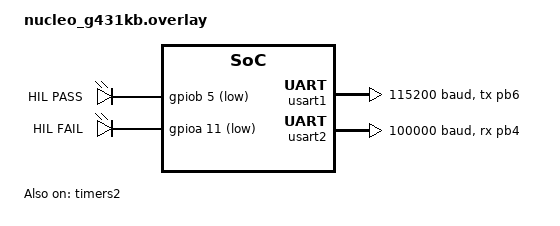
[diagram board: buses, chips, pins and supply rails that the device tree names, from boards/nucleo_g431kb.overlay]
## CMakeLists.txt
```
# SPDX-License-Identifier: Apache-2.0

cmake_minimum_required(VERSION 3.28.0)
find_package(Zephyr REQUIRED HINTS $ENV{ZEPHYR_BASE})
project(sbus_bridge_hil)

target_sources(app PRIVATE
  src/main.c
  src/frame.c
)
```

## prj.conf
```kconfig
# SPDX-License-Identifier: Apache-2.0

CONFIG_ZTEST=y
CONFIG_ZTEST_FAIL_FAST=y
CONFIG_SHELL=y
CONFIG_REBOOT=y
CONFIG_SERIAL=y
CONFIG_UART_INTERRUPT_DRIVEN=y
CONFIG_CRC=y
CONFIG_GPIO=y
CONFIG_COUNTER=y
CONFIG_COUNTER_CAPTURE=y
```

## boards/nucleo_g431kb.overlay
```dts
/*
 * SPDX-License-Identifier: Apache-2.0
 *
 * Wiring (with DUT sbus_bridge):
 *   PB6 (D6)   USART1 TX 115200 8N1         -> DUT UART in
 *   PB4 (D12)  USART2 RX 100k 8E2 rx-invert <- DUT S.BUS out
 *   PA0 (A0)   TIM2_CH1 jumpered to PB6 (UART start, falling)
 *   PA1 (A1)   TIM2_CH2 jumpered to PB4 (S.BUS start, rising)
 *   PB5 (D11)  green status LED, OD active-low to +5 V
 *   PA11 (D10) red status LED, OD active-low to +5 V
 * Console LPUART1 PA2/PA3 untouched.
 */

#include <zephyr/dt-bindings/gpio/gpio.h>

/ {
	aliases {
		uart-out = &usart1;
		sbus-in = &usart2;
		led-green = &hil_led_green;
		led-red = &hil_led_red;
	};
};

&leds {
	hil_led_green: led_green {
		gpios = <&gpiob 5 (GPIO_OPEN_DRAIN | GPIO_ACTIVE_LOW)>;
		label = "HIL PASS";
	};

	hil_led_red: led_red {
		gpios = <&gpioa 11 (GPIO_OPEN_DRAIN | GPIO_ACTIVE_LOW)>;
		label = "HIL FAIL";
	};
};

&usart1 {
	pinctrl-0 = <&usart1_tx_pb6>;
	pinctrl-names = "default";
	current-speed = <115200>;
	fifo-enable;
	interrupts = <37 1>;
	status = "okay";
};

&usart2 {
	pinctrl-0 = <&usart2_rx_pb4>;
	pinctrl-names = "default";
	current-speed = <100000>;
	parity = "even";
	stop-bits = "2";
	rx-invert;
	fifo-enable;
	interrupts = <38 1>;
	status = "okay";
};

&timers2 {
	st,prescaler = <16>;
	status = "okay";

	counter2: counter {
		status = "okay";
		pinctrl-0 = <&tim2_ch1_pa0 &tim2_ch2_pa1>;
		pinctrl-names = "default";
	};
};
```

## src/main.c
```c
/*
 * SPDX-License-Identifier: Apache-2.0
 */

#include <stdbool.h>
#include <stddef.h>
#include <stdint.h>

#include <zephyr/kernel.h>
#include <zephyr/sys/util.h>
#include <zephyr/ztest.h>

#include "capture.h"
#include "frame.h"
#include "status_led.h"
#include "wire.h"

#define HIL_STREAM_N               100
#define HIL_PACED_PERIOD_MS        5 /* 200 Hz */
#define HIL_PACED_SEND_GAP_MIN_US  3000
#define HIL_PACED_SEND_GAP_MAX_US  7000
#define HIL_RTT_MIN_US             50
#define HIL_RTT_MAX_US             200
#define HIL_GAPLESS_RX_MIN         70
#define HIL_GAPLESS_RX_MAX         80
#define HIL_GAPLESS_SEND_GAP_MIN_US 1000
#define HIL_GAPLESS_SEND_GAP_MAX_US 6000
#define HIL_UART_BYTE_US           87 /* 10/115200 ~= 86.8 */
#define HIL_FRAME_UART_US          (HIL_FRAME_LEN * HIL_UART_BYTE_US)
#define HIL_IDLE_MS                20
#define HIL_SETTLE_MS              5
#define HIL_FIRST_FRAME_TO_MS      50
#define HIL_SETTLE_TIMEOUT_MS      2000
#define HIL_CAPTURE_TIMEOUT_MS     20
#define HIL_NOISE_N                512
#define HIL_NOISE_SEED             0xC0FFEEu
#define HIL_NOISE_SEQ              0x4E01u

static bool eol_any_failed(void)
{
	struct ztest_unit_test *test = NULL;

	while ((test = z_ztest_get_next_test("eol", test)) != NULL) {
		if (test->stats->fail_count > 0U) {
			return true;
		}
	}

	return false;
}

static uint32_t now_us(void)
{
	/* 32-bit cycle-to-us wraps in ~25 s; short-stream diffs are modular. */
	return k_cyc_to_us_near32(k_cycle_get_32());
}

/* Wait until no RX byte has been seen for HIL_SETTLE_MS. */
static void settle(void)
{
	int64_t deadline = k_uptime_get() + HIL_SETTLE_TIMEOUT_MS;

	while (k_uptime_get() < deadline) {
		int64_t last = hil_wire_last_rx_ms();

		if (last < 0 || (k_uptime_get() - last) >= HIL_SETTLE_MS) {
			return;
		}
		k_msleep(1);
	}

	zassert_unreachable("DUT output did not settle within %d ms", HIL_SETTLE_TIMEOUT_MS);
}

static void *eol_setup(void)
{
	zassert_ok(hil_status_leds_init());
	hil_status_leds_off();

	zassert_ok(hil_wire_init());
	/* Close any stuck DUT COLLECT window left by a prior failed run. */
	zassert_ok(hil_wire_drain());
	/* Drain may start a junk S.BUS frame after our TX completes. */
	k_msleep(HIL_SETTLE_MS);
	settle();
	hil_wire_reset();
	zassert_ok(hil_capture_init());
	return NULL;
}

static void eol_teardown(void *data)
{
	ARG_UNUSED(data);

	if (eol_any_failed()) {
		hil_status_leds_fail();
	} else {
		hil_status_leds_pass();
	}
}

static void assert_stream(const char *name, uint32_t sent_last, size_t rx_min, size_t rx_max,
			  uint32_t seq_gap_max, uint32_t send_gap_min_us, uint32_t send_gap_max_us,
			  bool check_idle)
{
	uint32_t seq_gap_lo = UINT32_MAX;
	uint32_t seq_gap_hi = 0U;
	uint32_t send_gap_lo = UINT32_MAX;
	uint32_t send_gap_hi = 0U;
	uint32_t prev_seq = 0U;
	uint32_t prev_t_us = 0U;
	uint32_t seq = 0U;
	uint32_t t_us = 0U;
	size_t count;

	/* Let the tail of the DUT output arrive before judging the stream. */
	settle();

	int64_t idle_since = hil_wire_last_rx_ms() + 1;
	size_t rx_at_settle = hil_wire_rx_count();
	uint32_t corrupt_at_settle = hil_wire_corrupt_count();

	zassert_equal(corrupt_at_settle, 0, "%s: corrupt frames/bytes seen", name);

	count = hil_wire_rx_count();
	zassert_true(count >= rx_min && count <= rx_max, "%s: rx_count %zu outside [%zu, %zu]",
		     name, count, rx_min, rx_max);

	for (size_t i = 0; i < count; i++) {
		zassert_true(hil_wire_rx_get(i, &seq, &t_us), "%s: rx_get(%zu) failed", name, i);

		if (i > 0) {
			uint32_t seq_gap = seq - prev_seq;
			uint32_t send_gap = t_us - prev_t_us; /* modular */

			zassert_true(seq > prev_seq && seq_gap >= 1U && seq_gap <= seq_gap_max,
				     "%s: seq gap %u at rx %zu (seq %u -> %u), max %u", name,
				     seq_gap, i, prev_seq, seq, seq_gap_max);
			zassert_true(send_gap >= send_gap_min_us && send_gap <= send_gap_max_us,
				     "%s: send gap %u us at rx %zu (seq %u -> %u), want [%u, %u]",
				     name, send_gap, i, prev_seq, seq, send_gap_min_us,
				     send_gap_max_us);

			seq_gap_lo = MIN(seq_gap_lo, seq_gap);
			seq_gap_hi = MAX(seq_gap_hi, seq_gap);
			send_gap_lo = MIN(send_gap_lo, send_gap);
			send_gap_hi = MAX(send_gap_hi, send_gap);
		}

		prev_seq = seq;
		prev_t_us = t_us;
	}

	zassert_equal(seq, sent_last, "%s: last seq %u != sent %u", name, seq, sent_last);

	TC_PRINT("%s: rx=%zu seq_gap[min=%u max=%u] send_gap_us[min=%u max=%u]\n", name, count,
		 seq_gap_lo, seq_gap_hi, send_gap_lo, send_gap_hi);

	if (check_idle) {
		k_msleep(HIL_IDLE_MS);
		zassert_true(hil_wire_idle_since(idle_since, HIL_IDLE_MS),
			     "%s: unexpected RX after final frame", name);
		zassert_equal(hil_wire_rx_count(), rx_at_settle, "%s: rx_count changed during idle",
			      name);
		zassert_equal(hil_wire_corrupt_count(), corrupt_at_settle,
			      "%s: corrupt count changed during idle", name);
	}
}

ZTEST(eol, test_frame_crc_vector)
{
	uint8_t frame[HIL_FRAME_LEN];
	uint32_t seq;
	uint32_t t_us;
	static const uint8_t expect[HIL_FRAME_LEN] = {
		0x0f, 0x00, 0x00, 0x00, 0x00, 0x04, 0x03, 0x02, 0x01,
		0x5a, 0x5a, 0x5a, 0x5a, 0x5a, 0x5a, 0x5a, 0x5a, 0x5a,
		0x5a, 0x5a, 0x5a, 0x04, 0x2b, 0x00, 0x00,
	};

	hil_frame_encode(frame, 0, 0x01020304);
	zassert_mem_equal(frame, expect, HIL_FRAME_LEN);
	zassert_true(hil_frame_check(frame, &seq, &t_us));
	zassert_equal(seq, 0);
	zassert_equal(t_us, 0x01020304);
	frame[21] ^= 0x01;
	zassert_false(hil_frame_check(frame, &seq, &t_us));
}

ZTEST(eol, test_cut_through)
{
	uint8_t frame[HIL_FRAME_LEN];
	uint32_t t_uart;
	uint32_t t_sbus;
	uint32_t seq;
	uint32_t t_us;
	uint32_t rtt_us;

	settle();
	hil_wire_reset();
	zassert_ok(hil_capture_arm());

	hil_frame_encode(frame, 0, now_us());
	/* Armed before send so the UART falling edge is not missed. */
	zassert_ok(hil_wire_send_frame(frame));

	zassert_ok(hil_capture_wait(&t_uart, &t_sbus, K_MSEC(HIL_CAPTURE_TIMEOUT_MS)));
	hil_capture_disarm();

	/* Cut-through: S.BUS start appears before the input frame would have finished. */
	rtt_us = hil_capture_ticks_to_us(t_sbus - t_uart); /* modular 32-bit subtract */
	zassert_true(rtt_us < HIL_FRAME_UART_US, "rtt %u us is not < frame time %u us", rtt_us,
		     HIL_FRAME_UART_US);

	/* The whole valid frame must follow. */
	zassert_true(WAIT_FOR(hil_wire_rx_count() >= 1, 50000, k_msleep(1)),
		     "no complete frame on S.BUS");
	settle();
	zassert_equal(hil_wire_rx_count(), 1);
	zassert_equal(hil_wire_corrupt_count(), 0);
	zassert_true(hil_wire_rx_get(0, &seq, &t_us));
	zassert_equal(seq, 0);

	TC_PRINT("cut-through rtt=%u us\n", rtt_us);
}

ZTEST(eol, test_paced)
{
	uint8_t frame[HIL_FRAME_LEN];
	uint32_t rtt_min_us = UINT32_MAX;
	uint32_t rtt_max_us = 0U;
	int64_t start_ms;

	settle();
	hil_wire_reset();

	start_ms = k_uptime_get();
	for (uint32_t i = 0; i < HIL_STREAM_N; i++) {
		uint32_t t_uart;
		uint32_t t_sbus;
		uint32_t rtt_us;

		zassert_ok(hil_capture_arm());
		hil_frame_encode(frame, i, now_us());
		zassert_ok(hil_wire_send_frame(frame));
		zassert_ok(hil_capture_wait(&t_uart, &t_sbus, K_MSEC(HIL_CAPTURE_TIMEOUT_MS)),
			   "frame %u: no capture", i);
		hil_capture_disarm();

		rtt_us = hil_capture_ticks_to_us(t_sbus - t_uart);
		zassert_true(rtt_us >= HIL_RTT_MIN_US && rtt_us <= HIL_RTT_MAX_US,
			     "frame %u: rtt %u us outside [%u, %u]", i, rtt_us, HIL_RTT_MIN_US,
			     HIL_RTT_MAX_US);
		rtt_min_us = MIN(rtt_min_us, rtt_us);
		rtt_max_us = MAX(rtt_max_us, rtt_us);

		if (i == 0U) {
			/* First valid frame must be out within HIL_FIRST_FRAME_TO_MS of send. */
			zassert_true(WAIT_FOR(hil_wire_rx_count() >= 1,
					      (HIL_FIRST_FRAME_TO_MS -
					       (k_uptime_get() - start_ms)) * USEC_PER_MSEC,
					      k_msleep(1)),
				     "no valid frame within %d ms of first send",
				     HIL_FIRST_FRAME_TO_MS);
		}

		k_sleep(K_TIMEOUT_ABS_MS(start_ms + (int64_t)(i + 1U) * HIL_PACED_PERIOD_MS));
	}

	TC_PRINT("paced: rtt_us[min=%u max=%u]\n", rtt_min_us, rtt_max_us);

	assert_stream("paced", HIL_STREAM_N - 1, HIL_STREAM_N, HIL_STREAM_N, 1,
		      HIL_PACED_SEND_GAP_MIN_US, HIL_PACED_SEND_GAP_MAX_US, true);
}

ZTEST(eol, test_gapless)
{
	uint8_t frame[HIL_FRAME_LEN];

	settle();
	hil_wire_reset();
	hil_capture_disarm();

	for (uint32_t i = 0; i < HIL_STREAM_N; i++) {
		hil_frame_encode(frame, i, now_us());
		zassert_ok(hil_wire_send_frame(frame), "frame %u: send failed", i);
	}

	assert_stream("gapless", HIL_STREAM_N - 1, HIL_GAPLESS_RX_MIN, HIL_GAPLESS_RX_MAX, 2,
		      HIL_GAPLESS_SEND_GAP_MIN_US, HIL_GAPLESS_SEND_GAP_MAX_US, true);
}

/* xorshift32; not crypto — reproducible flood for HIL. */
static uint32_t xorshift32(uint32_t *state)
{
	uint32_t x = *state;

	x ^= x << 13;
	x ^= x >> 17;
	x ^= x << 5;
	*state = x;
	return x;
}

static void flood_noise(bool allow_header)
{
	uint8_t chunk[HIL_FRAME_LEN];
	uint32_t rng = HIL_NOISE_SEED;
	size_t left = HIL_NOISE_N;

	while (left > 0U) {
		size_t n = MIN(left, sizeof(chunk));

		for (size_t i = 0; i < n; i++) {
			uint8_t b = (uint8_t)xorshift32(&rng);

			if (!allow_header && b == HIL_HDR) {
				b ^= 0x01U;
			}
			chunk[i] = b;
		}
		zassert_ok(hil_wire_send_bytes(chunk, n), "noise send failed (%zu left)", left);
		left -= n;
	}
}

static void assert_recovery_frame(const char *name)
{
	uint8_t frame[HIL_FRAME_LEN];
	uint32_t seq;
	uint32_t t_us;

	hil_frame_encode(frame, HIL_NOISE_SEQ, now_us());
	zassert_ok(hil_wire_send_frame(frame));

	zassert_true(WAIT_FOR(hil_wire_rx_count() >= 1, 50000, k_msleep(1)),
		     "%s: no complete frame on S.BUS after recovery send", name);
	settle();
	zassert_equal(hil_wire_rx_count(), 1, "%s: expected exactly one logged frame", name);
	zassert_equal(hil_wire_corrupt_count(), 0, "%s: corrupt after recovery", name);
	zassert_true(hil_wire_rx_get(0, &seq, &t_us), "%s: rx_get failed", name);
	zassert_equal(seq, HIL_NOISE_SEQ, "%s: seq %u != %u", name, seq, HIL_NOISE_SEQ);

	TC_PRINT("%s: recovered seq=%u\n", name, seq);
}

ZTEST(eol, test_noise_no_header)
{
	/* Case C: noise without 0x0F keeps DUT in HUNT; one valid frame must pass. */
	settle();
	hil_wire_reset();
	hil_capture_disarm();

	flood_noise(false);
	settle();
	hil_wire_reset();

	assert_recovery_frame("noise_no_header");
}

ZTEST(eol, test_noise_resync)
{
	/* Case A: unrestricted noise may mid-COLLECT; drain then one valid frame. */
	settle();
	hil_wire_reset();
	hil_capture_disarm();

	flood_noise(true);
	zassert_ok(hil_wire_drain());
	k_msleep(HIL_SETTLE_MS);
	settle();
	hil_wire_reset();

	assert_recovery_frame("noise_resync");
}

ZTEST_SUITE(eol, NULL, eol_setup, NULL, NULL, eol_teardown);
```

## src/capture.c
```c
/*
 * SPDX-License-Identifier: Apache-2.0
 */

#include "capture.h"

#include <zephyr/device.h>
#include <zephyr/drivers/counter.h>
#include <zephyr/sys/atomic.h>
#include <zephyr/sys/util.h>

#define UART_CAPTURE_CHANNEL  0U
#define SBUS_CAPTURE_CHANNEL  1U
#define CAPTURE_COMPLETE_MASK (BIT(UART_CAPTURE_CHANNEL) | BIT(SBUS_CAPTURE_CHANNEL))

static const struct device *const capture_dev = DEVICE_DT_GET(DT_NODELABEL(counter2));
static uint32_t uart_ticks;
static uint32_t sbus_ticks;
static atomic_t capture_mask;
K_SEM_DEFINE(capture_done, 0, 1);

/*
 * The STM32 Zephyr counter driver does not expose CCxOF here, so overcapture
 * cannot fail a case; a missed edge still times out from hil_capture_wait()
 * with -EAGAIN.
 */
static void capture_cb(const struct device *dev, uint8_t channel,
		       counter_capture_flags_t flags, uint32_t ticks, void *user_data)
{
	atomic_val_t previous;

	ARG_UNUSED(dev);
	ARG_UNUSED(flags);
	ARG_UNUSED(user_data);

	if (channel != UART_CAPTURE_CHANNEL && channel != SBUS_CAPTURE_CHANNEL) {
		return;
	}

	if (channel == UART_CAPTURE_CHANNEL) {
		uart_ticks = ticks;
	} else {
		sbus_ticks = ticks;
	}

	previous = atomic_or(&capture_mask, BIT(channel));
	if ((previous | BIT(channel)) == CAPTURE_COMPLETE_MASK) {
		k_sem_give(&capture_done);
	}
}

static int capture_configure(void)
{
	int ret;

	ret = counter_capture_configure(capture_dev, UART_CAPTURE_CHANNEL,
					COUNTER_CAPTURE_FALLING_EDGE | COUNTER_CAPTURE_SINGLE_SHOT,
					capture_cb, NULL);
	if (ret != 0) {
		return ret;
	}

	ret = counter_capture_configure(capture_dev, SBUS_CAPTURE_CHANNEL,
					COUNTER_CAPTURE_RISING_EDGE | COUNTER_CAPTURE_SINGLE_SHOT,
					capture_cb, NULL);
	if (ret != 0) {
		(void)counter_disable_capture(capture_dev, UART_CAPTURE_CHANNEL);
	}

	return ret;
}

int hil_capture_init(void)
{
	int ret;

	if (!device_is_ready(capture_dev)) {
		return -ENODEV;
	}

	ret = capture_configure();
	if (ret != 0) {
		return ret;
	}

	ret = counter_start(capture_dev);
	if (ret != 0) {
		hil_capture_disarm();
	}

	return ret;
}

int hil_capture_arm(void)
{
	int ret;

	hil_capture_disarm();

	ret = capture_configure();
	if (ret != 0) {
		return ret;
	}

	k_sem_reset(&capture_done);
	atomic_clear(&capture_mask);
	uart_ticks = 0U;
	sbus_ticks = 0U;

	ret = counter_enable_capture(capture_dev, UART_CAPTURE_CHANNEL);
	if (ret != 0) {
		hil_capture_disarm();
		return ret;
	}

	ret = counter_enable_capture(capture_dev, SBUS_CAPTURE_CHANNEL);
	if (ret != 0) {
		hil_capture_disarm();
	}

	return ret;
}

int hil_capture_wait(uint32_t *t_uart, uint32_t *t_sbus, k_timeout_t timeout)
{
	int ret;

	if (t_uart == NULL || t_sbus == NULL) {
		return -EINVAL;
	}

	ret = k_sem_take(&capture_done, timeout);
	if (ret != 0) {
		return -EAGAIN;
	}

	if (atomic_get(&capture_mask) != CAPTURE_COMPLETE_MASK) {
		return -EIO;
	}

	*t_uart = uart_ticks;
	*t_sbus = sbus_ticks;
	return 0;
}

uint32_t hil_capture_ticks_to_us(uint32_t ticks)
{
	return (uint32_t)counter_ticks_to_us(capture_dev, ticks);
}

void hil_capture_disarm(void)
{
	(void)counter_disable_capture(capture_dev, UART_CAPTURE_CHANNEL);
	(void)counter_disable_capture(capture_dev, SBUS_CAPTURE_CHANNEL);
}
```

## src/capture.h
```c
/*
 * SPDX-License-Identifier: Apache-2.0
 */

#ifndef SBUS_BRIDGE_HIL_CAPTURE_H_
#define SBUS_BRIDGE_HIL_CAPTURE_H_

#include <stdint.h>

#include <zephyr/kernel.h>

int hil_capture_init(void);
int hil_capture_arm(void);
int hil_capture_wait(uint32_t *t_uart, uint32_t *t_sbus, k_timeout_t timeout);
uint32_t hil_capture_ticks_to_us(uint32_t ticks);
void hil_capture_disarm(void);

#endif
```

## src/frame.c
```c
/*
 * SPDX-License-Identifier: Apache-2.0
 */

#include "frame.h"

#include <string.h>

#include <zephyr/sys/byteorder.h>
#include <zephyr/sys/crc.h>

void hil_frame_encode(uint8_t out[HIL_FRAME_LEN], uint32_t seq, uint32_t t_us)
{
	uint16_t crc;

	out[0] = HIL_HDR;
	sys_put_le32(seq, &out[1]);
	sys_put_le32(t_us, &out[5]);
	memset(&out[9], HIL_FILL, 12);
	crc = crc16_itu_t(0xFFFF, &out[1], 20);
	sys_put_le16(crc, &out[21]);
	out[23] = 0x00;
	out[24] = HIL_FTR;
}

bool hil_frame_check(const uint8_t in[HIL_FRAME_LEN], uint32_t *seq, uint32_t *t_us)
{
	uint16_t expect;

	if (in[0] != HIL_HDR || in[23] != 0x00 || in[24] != HIL_FTR) {
		return false;
	}
	expect = crc16_itu_t(0xFFFF, &in[1], 20);
	if (sys_get_le16(&in[21]) != expect) {
		return false;
	}
	*seq = sys_get_le32(&in[1]);
	*t_us = sys_get_le32(&in[5]);
	return true;
}
```

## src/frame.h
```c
/*
 * SPDX-License-Identifier: Apache-2.0
 */

#ifndef SBUS_BRIDGE_HIL_FRAME_H_
#define SBUS_BRIDGE_HIL_FRAME_H_

#include <stdbool.h>
#include <stdint.h>

#define HIL_FRAME_LEN 25
#define HIL_HDR       0x0F
#define HIL_FTR       0x00
#define HIL_FILL      0x5A

void hil_frame_encode(uint8_t out[HIL_FRAME_LEN], uint32_t seq, uint32_t t_us);
bool hil_frame_check(const uint8_t in[HIL_FRAME_LEN], uint32_t *seq, uint32_t *t_us);

#endif
```

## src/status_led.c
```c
/*
 * SPDX-License-Identifier: Apache-2.0
 */

#include "status_led.h"

#include <zephyr/device.h>
#include <zephyr/drivers/gpio.h>

#define LED_GREEN_NODE DT_ALIAS(led_green)
#define LED_RED_NODE   DT_ALIAS(led_red)

BUILD_ASSERT(DT_NODE_EXISTS(LED_GREEN_NODE), "alias led-green missing");
BUILD_ASSERT(DT_NODE_EXISTS(LED_RED_NODE), "alias led-red missing");

static const struct gpio_dt_spec led_green = GPIO_DT_SPEC_GET(LED_GREEN_NODE, gpios);
static const struct gpio_dt_spec led_red = GPIO_DT_SPEC_GET(LED_RED_NODE, gpios);

int hil_status_leds_init(void)
{
	if (!gpio_is_ready_dt(&led_green) || !gpio_is_ready_dt(&led_red)) {
		return -ENODEV;
	}

	if (gpio_pin_configure_dt(&led_green, GPIO_OUTPUT_INACTIVE) < 0 ||
	    gpio_pin_configure_dt(&led_red, GPIO_OUTPUT_INACTIVE) < 0) {
		return -EIO;
	}

	return 0;
}

void hil_status_leds_off(void)
{
	(void)gpio_pin_set_dt(&led_green, 0);
	(void)gpio_pin_set_dt(&led_red, 0);
}

void hil_status_leds_pass(void)
{
	(void)gpio_pin_set_dt(&led_red, 0);
	(void)gpio_pin_set_dt(&led_green, 1);
}

void hil_status_leds_fail(void)
{
	(void)gpio_pin_set_dt(&led_green, 0);
	(void)gpio_pin_set_dt(&led_red, 1);
}
```

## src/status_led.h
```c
/*
 * SPDX-License-Identifier: Apache-2.0
 */

#ifndef SBUS_BRIDGE_HIL_STATUS_LED_H_
#define SBUS_BRIDGE_HIL_STATUS_LED_H_

int hil_status_leds_init(void);
void hil_status_leds_off(void);
void hil_status_leds_pass(void);
void hil_status_leds_fail(void);

#endif
```

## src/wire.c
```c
/*
 * SPDX-License-Identifier: Apache-2.0
 */

#include "wire.h"

#include <errno.h>
#include <string.h>

#include <zephyr/device.h>
#include <zephyr/drivers/uart.h>
#include <zephyr/kernel.h>
#include <zephyr/sys/atomic.h>
#include <zephyr/sys/util.h>

#define UART_OUT_NODE  DT_ALIAS(uart_out)
#define SBUS_IN_NODE   DT_ALIAS(sbus_in)
#define HIL_RX_LOG_MAX 128

BUILD_ASSERT(DT_NODE_EXISTS(UART_OUT_NODE), "alias uart-out missing");
BUILD_ASSERT(DT_NODE_EXISTS(SBUS_IN_NODE), "alias sbus-in missing");
BUILD_ASSERT(DT_IRQ(UART_OUT_NODE, priority) == 1, "uart-out IRQ priority must be 1");
BUILD_ASSERT(DT_IRQ(SBUS_IN_NODE, priority) == 1, "sbus-in IRQ priority must be 1");

struct hil_rx_entry {
	uint32_t seq;
	uint32_t t_us;
};

static const struct device *const uart_out = DEVICE_DT_GET(UART_OUT_NODE);
static const struct device *const sbus_in = DEVICE_DT_GET(SBUS_IN_NODE);
static struct hil_rx_entry rx_log[HIL_RX_LOG_MAX];
static atomic_t rx_count;
static atomic_t corrupt_count;
static uint8_t rx_frame[HIL_FRAME_LEN];
static size_t rx_pos;
static int64_t last_rx_ms = -1;
static uint8_t tx_buf[HIL_FRAME_LEN];
static size_t tx_len;
static size_t tx_pos;
K_SEM_DEFINE(tx_done, 0, 1);
K_MUTEX_DEFINE(tx_lock);

static void uart_out_cb(const struct device *dev, void *user_data)
{
	int sent;

	ARG_UNUSED(user_data);

	uart_irq_update(dev);
	while (tx_pos < tx_len && uart_irq_tx_ready(dev) > 0) {
		sent = uart_fifo_fill(dev, &tx_buf[tx_pos], tx_len - tx_pos);
		if (sent <= 0) {
			break;
		}
		tx_pos += (size_t)sent;
	}

	if (tx_pos == tx_len) {
		uart_irq_tx_disable(dev);
		k_sem_give(&tx_done);
	}
}

static int hil_wire_send(const uint8_t *data, size_t len)
{
	int ret;

	if (data == NULL || len == 0U || len > sizeof(tx_buf)) {
		return -EINVAL;
	}

	k_mutex_lock(&tx_lock, K_FOREVER);
	k_sem_reset(&tx_done);
	memcpy(tx_buf, data, len);
	tx_len = len;
	tx_pos = 0U;
	uart_irq_tx_enable(uart_out);
	ret = k_sem_take(&tx_done, K_MSEC(50));
	if (ret != 0) {
		uart_irq_tx_disable(uart_out);
	}
	k_mutex_unlock(&tx_lock);

	return ret;
}

static void rx_byte(uint8_t byte)
{
	uint32_t seq;
	uint32_t t_us;
	atomic_val_t count;

	last_rx_ms = k_uptime_get();

	if (rx_pos == 0U && byte != HIL_HDR) {
		atomic_inc(&corrupt_count);
		return;
	}

	rx_frame[rx_pos++] = byte;
	if (rx_pos < HIL_FRAME_LEN) {
		return;
	}

	rx_pos = 0U;
	if (!hil_frame_check(rx_frame, &seq, &t_us)) {
		atomic_inc(&corrupt_count);
		return;
	}

	count = atomic_get(&rx_count);
	if (count < HIL_RX_LOG_MAX) {
		rx_log[count].seq = seq;
		rx_log[count].t_us = t_us;
		atomic_inc(&rx_count);
	}
}

static void sbus_in_cb(const struct device *dev, void *user_data)
{
	uint8_t bytes[16];
	int err;
	int len;

	ARG_UNUSED(user_data);

	uart_irq_update(dev);
	err = uart_err_check(dev);
	if ((err & (UART_ERROR_PARITY | UART_ERROR_FRAMING)) != 0) {
		atomic_inc(&corrupt_count);
		rx_pos = 0U;
	}

	while (uart_irq_rx_ready(dev) > 0) {
		len = uart_fifo_read(dev, bytes, sizeof(bytes));
		if (len <= 0) {
			break;
		}
		for (int i = 0; i < len; i++) {
			rx_byte(bytes[i]);
		}
	}
}

int hil_wire_init(void)
{
	int ret;

	if (!device_is_ready(uart_out) || !device_is_ready(sbus_in)) {
		return -ENODEV;
	}

	ret = uart_irq_callback_user_data_set(uart_out, uart_out_cb, NULL);
	if (ret != 0) {
		return ret;
	}
	ret = uart_irq_callback_user_data_set(sbus_in, sbus_in_cb, NULL);
	if (ret != 0) {
		return ret;
	}

	hil_wire_reset();
	uart_irq_err_enable(sbus_in);
	uart_irq_rx_enable(sbus_in);
	return 0;
}

void hil_wire_reset(void)
{
	unsigned int key = irq_lock();

	atomic_clear(&rx_count);
	atomic_clear(&corrupt_count);
	rx_pos = 0U;
	last_rx_ms = -1;

	irq_unlock(key);
}

int hil_wire_send_frame(const uint8_t frame[HIL_FRAME_LEN])
{
	return hil_wire_send(frame, HIL_FRAME_LEN);
}

int hil_wire_send_bytes(const uint8_t *data, size_t len)
{
	if (data == NULL && len > 0U) {
		return -EINVAL;
	}

	while (len > 0U) {
		size_t n = MIN(len, sizeof(tx_buf));
		int ret = hil_wire_send(data, n);

		if (ret != 0) {
			return ret;
		}
		data += n;
		len -= n;
	}

	return 0;
}

int hil_wire_drain(void)
{
	uint8_t pad[HIL_FRAME_LEN - 1U];

	/* 24 footers: finishes any mid-COLLECT window (needs at most 24 bytes
	 * when len==1). Footer 0x00 is valid S.BUS, so the DUT commits/emits
	 * that junk frame and returns to HUNT. While already hunting, 0x00 is
	 * discarded.
	 */
	memset(pad, HIL_FTR, sizeof(pad));
	return hil_wire_send(pad, sizeof(pad));
}

size_t hil_wire_rx_count(void)
{
	return (size_t)atomic_get(&rx_count);
}

bool hil_wire_rx_get(size_t i, uint32_t *seq, uint32_t *t_us)
{
	unsigned int key;

	if (seq == NULL || t_us == NULL) {
		return false;
	}

	key = irq_lock();
	if (i >= (size_t)atomic_get(&rx_count)) {
		irq_unlock(key);
		return false;
	}
	*seq = rx_log[i].seq;
	*t_us = rx_log[i].t_us;
	irq_unlock(key);
	return true;
}

uint32_t hil_wire_corrupt_count(void)
{
	return (uint32_t)atomic_get(&corrupt_count);
}

bool hil_wire_idle_since(int64_t since_ms, int32_t window_ms)
{
	int64_t now = k_uptime_get();
	int64_t last;

	if (window_ms < 0 || now < since_ms + window_ms) {
		return false;
	}

	last = hil_wire_last_rx_ms();
	return last < since_ms;
}

int64_t hil_wire_last_rx_ms(void)
{
	unsigned int key = irq_lock();
	int64_t last = last_rx_ms;

	irq_unlock(key);
	return last;
}
```

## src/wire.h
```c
/*
 * SPDX-License-Identifier: Apache-2.0
 */

#ifndef SBUS_BRIDGE_HIL_WIRE_H_
#define SBUS_BRIDGE_HIL_WIRE_H_

#include <stdbool.h>
#include <stddef.h>
#include <stdint.h>

#include "frame.h"

int hil_wire_init(void);
void hil_wire_reset(void);
int hil_wire_send_frame(const uint8_t frame[HIL_FRAME_LEN]);

/* Chunk-send an arbitrary buffer on uart-out (≤ HIL_FRAME_LEN per IRQ burst). */
int hil_wire_send_bytes(const uint8_t *data, size_t len);

/*
 * Force the DUT assembler back to HUNT: send 24 S.BUS footer bytes (0x00).
 * Completes any stuck COLLECT window (at most 24 bytes still owed); ignored
 * while the DUT is already hunting. May provoke one junk S.BUS frame.
 */
int hil_wire_drain(void);

size_t hil_wire_rx_count(void);
bool hil_wire_rx_get(size_t i, uint32_t *seq, uint32_t *t_us);
uint32_t hil_wire_corrupt_count(void);

/*
 * True when no RX byte occurred in [since_ms, since_ms + window_ms].
 *
 * Call only after the window has ended (k_uptime_get() >= since_ms + window_ms);
 * before that the function always returns false and does not sleep. After the
 * window, returns true iff hil_wire_last_rx_ms() < since_ms (any byte at or
 * after since_ms means the interval was not idle).
 */
bool hil_wire_idle_since(int64_t since_ms, int32_t window_ms);
int64_t hil_wire_last_rx_ms(void);

#endif
```
